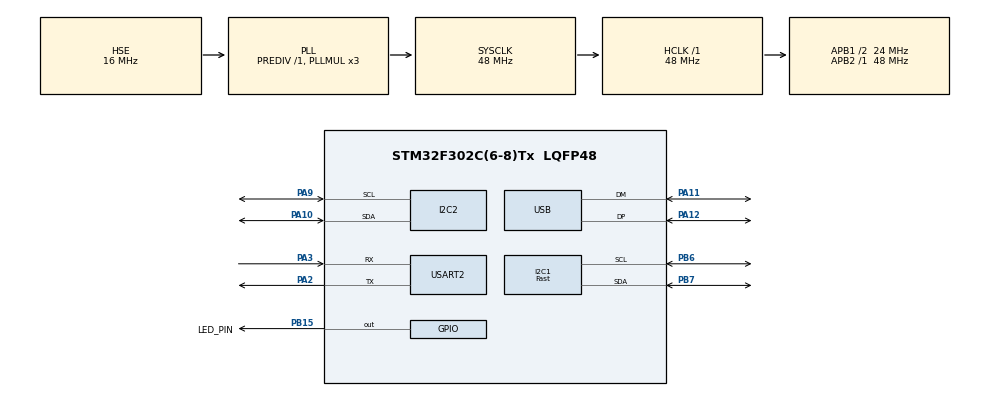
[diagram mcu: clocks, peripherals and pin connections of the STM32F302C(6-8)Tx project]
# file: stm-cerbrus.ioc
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I2C1.I2C_Speed_Mode=I2C_Fast
I2C1.Timing=0x2010091A
I2C2.Timing=0x20303E5D
Mcu.Family=STM32F3
Mcu.Name=STM32F302C(6-8)Tx
Mcu.Package=LQFP48
NVIC.PriorityGroup=NVIC_PRIORITYGROUP_4
PA10.Mode=I2C
PA10.Signal=I2C2_SDA
PA11.Mode=Device
PA11.Signal=USB_DM
PA12.Mode=Device
PA12.Signal=USB_DP
PA13.Signal=SYS_JTMS-SWDIO
PA14.Signal=SYS_JTCK-SWCLK
PA2.Mode=Asynchronous
PA2.Signal=USART2_TX
PA3.Mode=Asynchronous
PA3.Signal=USART2_RX
PA9.Mode=I2C
PA9.Signal=I2C2_SCL
PB15.GPIO_Label=LED_PIN
PB15.Signal=GPIO_Output
PB3.Signal=SYS_JTDO-TRACESWO
PB6.Mode=I2C
PB6.Signal=I2C1_SCL
PB7.Mode=I2C
PB7.Signal=I2C1_SDA
PF0-OSC_IN.Mode=HSE-External-Oscillator
PF0-OSC_IN.Signal=RCC_OSC_IN
PF1-OSC_OUT.Mode=HSE-External-Oscillator
PF1-OSC_OUT.Signal=RCC_OSC_OUT
ProjectManager.HeapSize=0x200
ProjectManager.StackSize=0x400
ProjectManager.TargetToolchain=STM32CubeIDE
RCC.AHBFreq_Value=48000000
RCC.APB1CLKDivider=RCC_HCLK_DIV2
RCC.APB1Freq_Value=24000000
RCC.APB1TimFreq_Value=48000000
RCC.APB2Freq_Value=48000000
RCC.APB2TimFreq_Value=48000000
RCC.CortexFreq_Value=48000000
RCC.HCLKFreq_Value=48000000
RCC.HSE_VALUE=16000000
RCC.HSI_VALUE=8000000
RCC.I2c1ClockSelection=RCC_I2C1CLKSOURCE_SYSCLK
RCC.I2c2ClockSelection=RCC_I2C2CLKSOURCE_SYSCLK
RCC.LSE_VALUE=32768
RCC.PLLMUL=RCC_PLL_MUL3
RCC.SYSCLKFreq_VALUE=48000000
RCC.SYSCLKSourceVirtual=RCC_SYSCLKSOURCE_PLLCLK
RCC.USBFreq_Value=48000000
USART2.VirtualMode-Asynchronous=VM_ASYNC
board=custom

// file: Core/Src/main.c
/* USER CODE BEGIN Header */
/**
  ******************************************************************************
  * @file           : main.c
  * @brief          : Main program body
  ******************************************************************************
  * @attention
  *
  * Copyright (c) 2022 STMicroelectronics.
  * All rights reserved.
  *
  * This software is licensed under terms that can be found in the LICENSE file
  * in the root directory of this software component.
  * If no LICENSE file comes with this software, it is provided AS-IS.
  *
  ******************************************************************************
  */
/* USER CODE END Header */
#include "main.h"

/* USER CODE BEGIN Includes */
#include "mpu6050.h"
/* USER CODE END Includes */

I2C_HandleTypeDef hi2c1;
I2C_HandleTypeDef hi2c2;

UART_HandleTypeDef huart2;

PCD_HandleTypeDef hpcd_USB_FS;

/* USER CODE BEGIN PV */
MPU6050_t MPU6050;
/* USER CODE END PV */

void SystemClock_Config(void);
static void MX_GPIO_Init(void);
static void MX_I2C1_Init(void);
static void MX_I2C2_Init(void);
static void MX_USB_PCD_Init(void);
static void MX_USART2_UART_Init(void);

int main(void)
{

  /* MCU Configuration--------------------------------------------------------*/

  /* Reset of all peripherals, Initializes the Flash interface and the Systick. */
  HAL_Init();

  /* Configure the system clock */
  SystemClock_Config();

  /* Initialize all configured peripherals */
  MX_GPIO_Init();
  MX_I2C1_Init();
  MX_I2C2_Init();
  MX_USB_PCD_Init();
  MX_USART2_UART_Init();
  /* USER CODE BEGIN 2 */
  while(MPU6050_Init(&hi2c1)==1);
  /* USER CODE END 2 */

  /* Infinite loop */
  while (1)
  {

    /* USER CODE BEGIN 3 */
	  MPU6050_Read_All(&hi2c1, &MPU6050);
	  HAL_GPIO_TogglePin(LED_PIN_GPIO_Port, LED_PIN_Pin); // Toggle LED PIN
	  HAL_Delay(1000); // 1000 ms Delay
  }
  /* USER CODE END 3 */
}

void SystemClock_Config(void)
{
  RCC_OscInitTypeDef RCC_OscInitStruct = {0};
  RCC_ClkInitTypeDef RCC_ClkInitStruct = {0};
  RCC_PeriphCLKInitTypeDef PeriphClkInit = {0};

  /** Initializes the RCC Oscillators according to the specified parameters
  * in the RCC_OscInitTypeDef structure.
  */
  RCC_OscInitStruct.OscillatorType = RCC_OSCILLATORTYPE_HSE;
  RCC_OscInitStruct.HSEState = RCC_HSE_ON;
  RCC_OscInitStruct.HSEPredivValue = RCC_HSE_PREDIV_DIV1;
  RCC_OscInitStruct.HSIState = RCC_HSI_ON;
  RCC_OscInitStruct.PLL.PLLState = RCC_PLL_ON;
  RCC_OscInitStruct.PLL.PLLSource = RCC_PLLSOURCE_HSE;
  RCC_OscInitStruct.PLL.PLLMUL = RCC_PLL_MUL3;
  if (HAL_RCC_OscConfig(&RCC_OscInitStruct) != HAL_OK)
  {
    Error_Handler();
  }

  /** Initializes the CPU, AHB and APB buses clocks
  */
  RCC_ClkInitStruct.ClockType = RCC_CLOCKTYPE_HCLK|RCC_CLOCKTYPE_SYSCLK
                              |RCC_CLOCKTYPE_PCLK1|RCC_CLOCKTYPE_PCLK2;
  RCC_ClkInitStruct.SYSCLKSource = RCC_SYSCLKSOURCE_PLLCLK;
  RCC_ClkInitStruct.AHBCLKDivider = RCC_SYSCLK_DIV1;
  RCC_ClkInitStruct.APB1CLKDivider = RCC_HCLK_DIV2;
  RCC_ClkInitStruct.APB2CLKDivider = RCC_HCLK_DIV1;

  if (HAL_RCC_ClockConfig(&RCC_ClkInitStruct, FLASH_LATENCY_1) != HAL_OK)
  {
    Error_Handler();
  }
  PeriphClkInit.PeriphClockSelection = RCC_PERIPHCLK_USB|RCC_PERIPHCLK_I2C1
                              |RCC_PERIPHCLK_I2C2;
  PeriphClkInit.I2c1ClockSelection = RCC_I2C1CLKSOURCE_SYSCLK;
  PeriphClkInit.I2c2ClockSelection = RCC_I2C2CLKSOURCE_SYSCLK;
  PeriphClkInit.USBClockSelection = RCC_USBCLKSOURCE_PLL;
  if (HAL_RCCEx_PeriphCLKConfig(&PeriphClkInit) != HAL_OK)
  {
    Error_Handler();
  }
}

static void MX_I2C1_Init(void)
{

  hi2c1.Instance = I2C1;
  hi2c1.Init.Timing = 0x2010091A;
  hi2c1.Init.OwnAddress1 = 0;
  hi2c1.Init.AddressingMode = I2C_ADDRESSINGMODE_7BIT;
  hi2c1.Init.DualAddressMode = I2C_DUALADDRESS_DISABLE;
  hi2c1.Init.OwnAddress2 = 0;
  hi2c1.Init.OwnAddress2Masks = I2C_OA2_NOMASK;
  hi2c1.Init.GeneralCallMode = I2C_GENERALCALL_DISABLE;
  hi2c1.Init.NoStretchMode = I2C_NOSTRETCH_DISABLE;
  if (HAL_I2C_Init(&hi2c1) != HAL_OK)
  {
    Error_Handler();
  }

  /** Configure Analogue filter
  */
  if (HAL_I2CEx_ConfigAnalogFilter(&hi2c1, I2C_ANALOGFILTER_ENABLE) != HAL_OK)
  {
    Error_Handler();
  }

  /** Configure Digital filter
  */
  if (HAL_I2CEx_ConfigDigitalFilter(&hi2c1, 0) != HAL_OK)
  {
    Error_Handler();
  }

}

static void MX_I2C2_Init(void)
{

  hi2c2.Instance = I2C2;
  hi2c2.Init.Timing = 0x20303E5D;
  hi2c2.Init.OwnAddress1 = 0;
  hi2c2.Init.AddressingMode = I2C_ADDRESSINGMODE_7BIT;
  hi2c2.Init.DualAddressMode = I2C_DUALADDRESS_DISABLE;
  hi2c2.Init.OwnAddress2 = 0;
  hi2c2.Init.OwnAddress2Masks = I2C_OA2_NOMASK;
  hi2c2.Init.GeneralCallMode = I2C_GENERALCALL_DISABLE;
  hi2c2.Init.NoStretchMode = I2C_NOSTRETCH_DISABLE;
  if (HAL_I2C_Init(&hi2c2) != HAL_OK)
  {
    Error_Handler();
  }

  /** Configure Analogue filter
  */
  if (HAL_I2CEx_ConfigAnalogFilter(&hi2c2, I2C_ANALOGFILTER_ENABLE) != HAL_OK)
  {
    Error_Handler();
  }

  /** Configure Digital filter
  */
  if (HAL_I2CEx_ConfigDigitalFilter(&hi2c2, 0) != HAL_OK)
  {
    Error_Handler();
  }

}

static void MX_USART2_UART_Init(void)
{

  huart2.Instance = USART2;
  huart2.Init.BaudRate = 38400;
  huart2.Init.WordLength = UART_WORDLENGTH_8B;
  huart2.Init.StopBits = UART_STOPBITS_1;
  huart2.Init.Parity = UART_PARITY_NONE;
  huart2.Init.Mode = UART_MODE_TX_RX;
  huart2.Init.HwFlowCtl = UART_HWCONTROL_NONE;
  huart2.Init.OverSampling = UART_OVERSAMPLING_16;
  huart2.Init.OneBitSampling = UART_ONE_BIT_SAMPLE_DISABLE;
  huart2.AdvancedInit.AdvFeatureInit = UART_ADVFEATURE_NO_INIT;
  if (HAL_UART_Init(&huart2) != HAL_OK)
  {
    Error_Handler();
  }

}

static void MX_USB_PCD_Init(void)
{

  hpcd_USB_FS.Instance = USB;
  hpcd_USB_FS.Init.dev_endpoints = 8;
  hpcd_USB_FS.Init.speed = PCD_SPEED_FULL;
  hpcd_USB_FS.Init.phy_itface = PCD_PHY_EMBEDDED;
  hpcd_USB_FS.Init.low_power_enable = DISABLE;
  hpcd_USB_FS.Init.battery_charging_enable = DISABLE;
  if (HAL_PCD_Init(&hpcd_USB_FS) != HAL_OK)
  {
    Error_Handler();
  }

}

static void MX_GPIO_Init(void)
{
  GPIO_InitTypeDef GPIO_InitStruct = {0};

  /* GPIO Ports Clock Enable */
  __HAL_RCC_GPIOF_CLK_ENABLE();
  __HAL_RCC_GPIOA_CLK_ENABLE();
  __HAL_RCC_GPIOB_CLK_ENABLE();

  /*Configure GPIO pin Output Level */
  HAL_GPIO_WritePin(LED_PIN_GPIO_Port, LED_PIN_Pin, GPIO_PIN_RESET);

  /*Configure GPIO pin : LED_PIN_Pin */
  GPIO_InitStruct.Pin = LED_PIN_Pin;
  GPIO_InitStruct.Mode = GPIO_MODE_OUTPUT_PP;
  GPIO_InitStruct.Pull = GPIO_NOPULL;
  GPIO_InitStruct.Speed = GPIO_SPEED_FREQ_LOW;
  HAL_GPIO_Init(LED_PIN_GPIO_Port, &GPIO_InitStruct);

}

void Error_Handler(void)
{
  __disable_irq();
  while (1)
  {
  }
}
